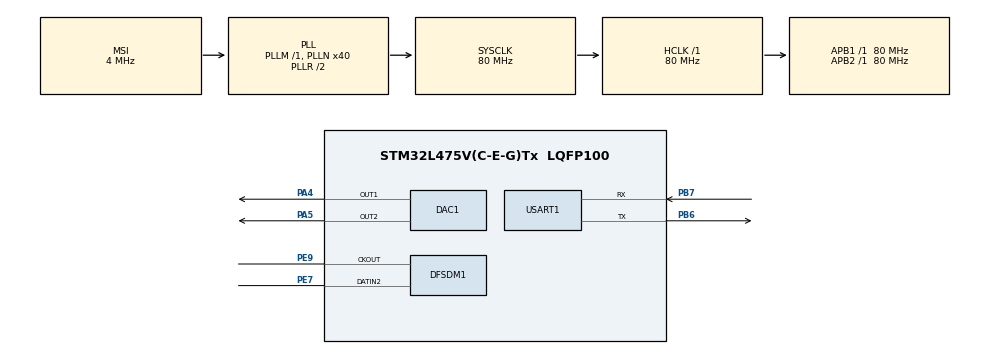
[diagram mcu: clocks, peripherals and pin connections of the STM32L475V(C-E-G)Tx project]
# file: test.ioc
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DAC1.DAC_Channel-DAC_OUT2=DAC_CHANNEL_2
DFSDM1.Divider=32
DFSDM1.FastMode_reg_FIL0=ENABLE
DFSDM1.FastMode_reg_FIL1=ENABLE
DFSDM1.Filter_regChannel_FIL0=DFSDM_CHANNEL_1
DFSDM1.Filter_regChannel_FIL1=DFSDM_CHANNEL_2
DFSDM1.Filter_regContinuousMode_FIL0=DFSDM_CONTINUOUS_CONV_ON
DFSDM1.Filter_regContinuousMode_FIL1=DFSDM_CONTINUOUS_CONV_ON
DFSDM1.Fosr_FIL0=128
DFSDM1.Fosr_FIL1=128
DFSDM1.Iosr_FIL0=1
DFSDM1.Iosr_FIL1=1
DFSDM1.RightBitShift_CH1=0x00
DFSDM1.RightBitShift_CH2=0x00
DFSDM1.Selection=DFSDM_CHANNEL_OUTPUT_CLOCK_AUDIO
DFSDM1.SincOrder_FIL0=DFSDM_FILTER_SINC4_ORDER
DFSDM1.SincOrder_FIL1=DFSDM_FILTER_SINC4_ORDER
DFSDM1.Type_spi_CH1=DFSDM_CHANNEL_SPI_FALLING
Mcu.Family=STM32L4
Mcu.Name=STM32L475V(C-E-G)Tx
Mcu.Package=LQFP100
NVIC.PriorityGroup=NVIC_PRIORITYGROUP_4
PA4.Signal=COMP_DAC11_group
PA5.Signal=COMP_DAC12_group
PB6.Mode=Asynchronous
PB6.Signal=USART1_TX
PB7.Mode=Asynchronous
PB7.Signal=USART1_RX
PE7.Signal=S_DATAIN2DFSDM1
PE9.Signal=S_CKOUTDFSDM1
ProjectManager.HeapSize=0x200
ProjectManager.StackSize=0x400
ProjectManager.TargetToolchain=MDK-ARM V5
RCC.ADCFreq_Value=64000000
RCC.AHBFreq_Value=80000000
RCC.APB1Freq_Value=80000000
RCC.APB1TimFreq_Value=80000000
RCC.APB2Freq_Value=80000000
RCC.APB2TimFreq_Value=80000000
RCC.CortexFreq_Value=80000000
RCC.HCLKFreq_Value=80000000
RCC.HSE_VALUE=8000000
RCC.HSI_VALUE=16000000
RCC.LSE_VALUE=32768
RCC.MSI_VALUE=4000000
RCC.PLLN=40
RCC.PLLSAI1N=32
RCC.SYSCLKFreq_VALUE=80000000
RCC.SYSCLKSource=RCC_SYSCLKSOURCE_PLLCLK
RCC.USBFreq_Value=64000000
RCC.VCOOutputFreq_Value=160000000
SH.COMP_DAC11_group.0=DAC1_OUT1,DAC_OUT1
SH.COMP_DAC12_group.0=DAC1_OUT2,DAC_OUT2
SH.S_CKOUTDFSDM1.0=DFSDM1_CKOUT,PDM_SPI_input_from_ch2_and_internal_clock
SH.S_CKOUTDFSDM1.1=DFSDM1_CKOUT,PDM_SPI_Input_from_ch12_and_Internal_Clock
SH.S_DATAIN2DFSDM1.0=DFSDM1_DATIN2,PDM_SPI_input_from_ch2_and_internal_clock
SH.S_DATAIN2DFSDM1.1=DFSDM1_DATIN2,PDM_SPI_Input_from_ch12_and_Internal_Clock
USART1.VirtualMode-Asynchronous=VM_ASYNC
board=custom

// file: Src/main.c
/**
 ******************************************************************************
 * @file           : main.c
 * @brief          : Main program body
 ******************************************************************************
 ** This notice applies to any and all portions of this file
 * that are not between comment pairs USER CODE BEGIN and
 * USER CODE END. Other portions of this file, whether
 * inserted by the user or by software development tools
 * are owned by their respective copyright owners.
 *
 * COPYRIGHT(c) 2018 STMicroelectronics
 *
 * Redistribution and use in source and binary forms, with or without modification,
 * are permitted provided that the following conditions are met:
 *   1. Redistributions of source code must retain the above copyright notice,
 *      this list of conditions and the following disclaimer.
 *   2. Redistributions in binary form must reproduce the above copyright notice,
 *      this list of conditions and the following disclaimer in the documentation
 *      and/or other materials provided with the distribution.
 *   3. Neither the name of STMicroelectronics nor the names of its contributors
 *      may be used to endorse or promote products derived from this software
 *      without specific prior written permission.
 *
 * THIS SOFTWARE IS PROVIDED BY THE COPYRIGHT HOLDERS AND CONTRIBUTORS "AS IS"
 * AND ANY EXPRESS OR IMPLIED WARRANTIES, INCLUDING, BUT NOT LIMITED TO, THE
 * IMPLIED WARRANTIES OF MERCHANTABILITY AND FITNESS FOR A PARTICULAR PURPOSE ARE
 * DISCLAIMED. IN NO EVENT SHALL THE COPYRIGHT HOLDER OR CONTRIBUTORS BE LIABLE
 * FOR ANY DIRECT, INDIRECT, INCIDENTAL, SPECIAL, EXEMPLARY, OR CONSEQUENTIAL
 * DAMAGES (INCLUDING, BUT NOT LIMITED TO, PROCUREMENT OF SUBSTITUTE GOODS OR
 * SERVICES; LOSS OF USE, DATA, OR PROFITS; OR BUSINESS INTERRUPTION) HOWEVER
 * CAUSED AND ON ANY THEORY OF LIABILITY, WHETHER IN CONTRACT, STRICT LIABILITY,
 * OR TORT (INCLUDING NEGLIGENCE OR OTHERWISE) ARISING IN ANY WAY OUT OF THE USE
 * OF THIS SOFTWARE, EVEN IF ADVISED OF THE POSSIBILITY OF SUCH DAMAGE.
 *
 ******************************************************************************
 */
#include "main.h"
#include "stm32l4xx_hal.h"
#include <math.h>

DAC_HandleTypeDef hdac1;

DFSDM_Filter_HandleTypeDef hdfsdm1_filter0;
DFSDM_Filter_HandleTypeDef hdfsdm1_filter1;
DFSDM_Channel_HandleTypeDef hdfsdm1_channel1;
DFSDM_Channel_HandleTypeDef hdfsdm1_channel2;

UART_HandleTypeDef huart1;

/* USER CODE BEGIN PV */
/* Private variables ---------------------------------------------------------*/

/* USER CODE END PV */

void SystemClock_Config(void);
static void MX_GPIO_Init(void);
static void MX_USART1_UART_Init(void);
static void MX_DFSDM1_Init(void);
static void MX_DAC1_Init(void);

/* USER CODE BEGIN PFP */
/* Private function prototypes -----------------------------------------------*/

/* USER CODE END PFP */

/* USER CODE BEGIN 0 */

int fputc(int ch, FILE *f) {
    while (HAL_OK != HAL_UART_Transmit(&huart1, (uint8_t *) &ch, 1, 30000));
    return ch;
}
int fgetc(FILE *f) {
    uint8_t ch = 0;
    while (HAL_OK != HAL_UART_Receive(&huart1, (uint8_t *)&ch, 1, 30000));
    return ch;
}

/* USER CODE END 0 */

int main(void)
{

    /* MCU Configuration----------------------------------------------------------*/

    /* Reset of all peripherals, Initializes the Flash interface and the Systick. */
    HAL_Init();

    /* Configure the system clock */
    SystemClock_Config();

    /* Initialize all configured peripherals */
    MX_GPIO_Init();
    MX_USART1_UART_Init();
    MX_DFSDM1_Init();
    MX_DAC1_Init();
    /* USER CODE BEGIN 2 */
    HAL_DAC_Start(&hdac1, DAC_CHANNEL_1);
    HAL_DAC_Start(&hdac1, DAC_CHANNEL_2);
    /* USER CODE END 2 */

    /* Infinite loop */
    /* USER CODE BEGIN WHILE */
    HAL_DFSDM_FilterRegularStart(&hdfsdm1_filter0);
    HAL_DFSDM_FilterRegularStart(&hdfsdm1_filter1);

		uint32_t channel0 = 1;
		uint32_t channel1 = 1;
		//int32_t prevflt0Result;
		//int32_t prevflt1Result;
		uint8_t flt0ResultBytes[4];
		uint8_t flt1ResultBytes[4];
		int32_t flt0Result;
		int32_t flt1Result;
		int32_t tempFlt0Result;
		int32_t tempFlt1Result;
		FILE *f;

    while (1)
    {
			//HAL_Delay(50);
			//fputc('c', f);
			//fputc('\n', f);

			//if(flt0Flag ==1){
			//fputc('a', f);
			//fputc('\n', f);

			while (HAL_DFSDM_FilterPollForRegConversion(&hdfsdm1_filter0, 30000) !=  HAL_OK) ;
			flt0Result = HAL_DFSDM_FilterGetRegularValue(&hdfsdm1_filter0, &channel0);
			HAL_DAC_SetValue(&hdac1,DAC_CHANNEL_1,DAC_ALIGN_12B_R,flt0Result);

			/**
			tempFlt0Result = flt0Result & 0xFFF;
			for (int i = 0; i < 4; i++) {
				flt0ResultBytes[3-i] = tempFlt0Result % 10 + '0';
				tempFlt0Result /= 10;
			}
			for (int i = 0; i < 4; i++)
				fputc(flt0ResultBytes[i], f);
			fputc('\n', f);
			*/

			while (HAL_DFSDM_FilterPollForRegConversion(&hdfsdm1_filter1, 30000) !=  HAL_OK) ;
			flt1Result = HAL_DFSDM_FilterGetRegularValue(&hdfsdm1_filter1, &channel1);
			HAL_DAC_SetValue(&hdac1,DAC_CHANNEL_2,DAC_ALIGN_12B_R,flt1Result);

			/**
			if (flt0Result > 200 || flt0Result < 1800) {
				HAL_DAC_SetValue(&hdac1,DAC_CHANNEL_1,DAC_ALIGN_12B_R,flt0Result);
				prevflt0Result = flt0Result;
			}
			else
				HAL_DAC_SetValue(&hdac1,DAC_CHANNEL_1,DAC_ALIGN_12B_R,prevflt0Result);
			**/

			/**
			while (HAL_DFSDM_FilterPollForRegConversion(&hdfsdm1_filter1, 30000) !=  HAL_OK) ;
			flt1Result = HAL_DFSDM_FilterGetRegularValue(&hdfsdm1_filter1, &channel1);
			flt0Result &= 0xFFF;

			if (flt0Result > 200 || flt0Result < 1800) {
				HAL_DAC_SetValue(&hdac1,DAC_CHANNEL_2,DAC_ALIGN_12B_R,flt1Result);
				prevflt1Result = flt1Result;
			}
			else
			HAL_DAC_SetValue(&hdac1,DAC_CHANNEL_2,DAC_ALIGN_12B_R,prevflt1Result);
			*/

			//		fputc(flt0Result, f);
    }
    /* USER CODE END 3 */

}

void SystemClock_Config(void)
{

    RCC_OscInitTypeDef RCC_OscInitStruct;
    RCC_ClkInitTypeDef RCC_ClkInitStruct;
    RCC_PeriphCLKInitTypeDef PeriphClkInit;

    /**Initializes the CPU, AHB and APB busses clocks
    */
    RCC_OscInitStruct.OscillatorType = RCC_OSCILLATORTYPE_MSI;
    RCC_OscInitStruct.MSIState = RCC_MSI_ON;
    RCC_OscInitStruct.MSICalibrationValue = 0;
    RCC_OscInitStruct.MSIClockRange = RCC_MSIRANGE_6;
    RCC_OscInitStruct.PLL.PLLState = RCC_PLL_ON;
    RCC_OscInitStruct.PLL.PLLSource = RCC_PLLSOURCE_MSI;
    RCC_OscInitStruct.PLL.PLLM = 1;
    RCC_OscInitStruct.PLL.PLLN = 40;
    RCC_OscInitStruct.PLL.PLLP = RCC_PLLP_DIV7;
    RCC_OscInitStruct.PLL.PLLQ = RCC_PLLQ_DIV2;
    RCC_OscInitStruct.PLL.PLLR = RCC_PLLR_DIV2;
    if (HAL_RCC_OscConfig(&RCC_OscInitStruct) != HAL_OK)
    {
        _Error_Handler(__FILE__, __LINE__);
    }

    /**Initializes the CPU, AHB and APB busses clocks
    */
    RCC_ClkInitStruct.ClockType = RCC_CLOCKTYPE_HCLK|RCC_CLOCKTYPE_SYSCLK
        |RCC_CLOCKTYPE_PCLK1|RCC_CLOCKTYPE_PCLK2;
    RCC_ClkInitStruct.SYSCLKSource = RCC_SYSCLKSOURCE_PLLCLK;
    RCC_ClkInitStruct.AHBCLKDivider = RCC_SYSCLK_DIV1;
    RCC_ClkInitStruct.APB1CLKDivider = RCC_HCLK_DIV1;
    RCC_ClkInitStruct.APB2CLKDivider = RCC_HCLK_DIV1;

    if (HAL_RCC_ClockConfig(&RCC_ClkInitStruct, FLASH_LATENCY_4) != HAL_OK)
    {
        _Error_Handler(__FILE__, __LINE__);
    }

    PeriphClkInit.PeriphClockSelection = RCC_PERIPHCLK_USART1|RCC_PERIPHCLK_SAI1
        |RCC_PERIPHCLK_DFSDM1;
    PeriphClkInit.Usart1ClockSelection = RCC_USART1CLKSOURCE_PCLK2;
    PeriphClkInit.Sai1ClockSelection = RCC_SAI1CLKSOURCE_PLLSAI1;
    PeriphClkInit.Dfsdm1ClockSelection = RCC_DFSDM1CLKSOURCE_PCLK;
    PeriphClkInit.PLLSAI1.PLLSAI1Source = RCC_PLLSOURCE_MSI;
    PeriphClkInit.PLLSAI1.PLLSAI1M = 1;
    PeriphClkInit.PLLSAI1.PLLSAI1N = 32;
    PeriphClkInit.PLLSAI1.PLLSAI1P = RCC_PLLP_DIV7;
    PeriphClkInit.PLLSAI1.PLLSAI1Q = RCC_PLLQ_DIV2;
    PeriphClkInit.PLLSAI1.PLLSAI1R = RCC_PLLR_DIV2;
    PeriphClkInit.PLLSAI1.PLLSAI1ClockOut = RCC_PLLSAI1_SAI1CLK;
    if (HAL_RCCEx_PeriphCLKConfig(&PeriphClkInit) != HAL_OK)
    {
        _Error_Handler(__FILE__, __LINE__);
    }

    /**Configure the main internal regulator output voltage
    */
    if (HAL_PWREx_ControlVoltageScaling(PWR_REGULATOR_VOLTAGE_SCALE1) != HAL_OK)
    {
        _Error_Handler(__FILE__, __LINE__);
    }

    /**Configure the Systick interrupt time
    */
    HAL_SYSTICK_Config(HAL_RCC_GetHCLKFreq()/1000);

    /**Configure the Systick
    */
    HAL_SYSTICK_CLKSourceConfig(SYSTICK_CLKSOURCE_HCLK);

    /* SysTick_IRQn interrupt configuration */
    HAL_NVIC_SetPriority(SysTick_IRQn, 0, 0);
}

/* DAC1 init function */
static void MX_DAC1_Init(void)
{

    DAC_ChannelConfTypeDef sConfig;

    /**DAC Initialization
    */
    hdac1.Instance = DAC1;
    if (HAL_DAC_Init(&hdac1) != HAL_OK)
    {
        _Error_Handler(__FILE__, __LINE__);
    }

    /**DAC channel OUT1 config
    */
    sConfig.DAC_SampleAndHold = DAC_SAMPLEANDHOLD_DISABLE;
    sConfig.DAC_Trigger = DAC_TRIGGER_NONE;
    sConfig.DAC_OutputBuffer = DAC_OUTPUTBUFFER_ENABLE;
    sConfig.DAC_ConnectOnChipPeripheral = DAC_CHIPCONNECT_DISABLE;
    sConfig.DAC_UserTrimming = DAC_TRIMMING_FACTORY;
    if (HAL_DAC_ConfigChannel(&hdac1, &sConfig, DAC_CHANNEL_1) != HAL_OK)
    {
        _Error_Handler(__FILE__, __LINE__);
    }

    /**DAC channel OUT2 config
    */
    sConfig.DAC_ConnectOnChipPeripheral = DAC_CHIPCONNECT_DISABLE;
    if (HAL_DAC_ConfigChannel(&hdac1, &sConfig, DAC_CHANNEL_2) != HAL_OK)
    {
        _Error_Handler(__FILE__, __LINE__);
    }

}

/* DFSDM1 init function */
static void MX_DFSDM1_Init(void)
{

    hdfsdm1_filter0.Instance = DFSDM1_Filter0;
    hdfsdm1_filter0.Init.RegularParam.Trigger = DFSDM_FILTER_SW_TRIGGER;
    hdfsdm1_filter0.Init.RegularParam.FastMode = ENABLE;
    hdfsdm1_filter0.Init.RegularParam.DmaMode = DISABLE;
    hdfsdm1_filter0.Init.FilterParam.SincOrder = DFSDM_FILTER_SINC4_ORDER;
    hdfsdm1_filter0.Init.FilterParam.Oversampling = 128;
    hdfsdm1_filter0.Init.FilterParam.IntOversampling = 1;
    if (HAL_DFSDM_FilterInit(&hdfsdm1_filter0) != HAL_OK)
    {
        _Error_Handler(__FILE__, __LINE__);
    }

    hdfsdm1_filter1.Instance = DFSDM1_Filter1;
    hdfsdm1_filter1.Init.RegularParam.Trigger = DFSDM_FILTER_SW_TRIGGER;
    hdfsdm1_filter1.Init.RegularParam.FastMode = ENABLE;
    hdfsdm1_filter1.Init.RegularParam.DmaMode = DISABLE;
    hdfsdm1_filter1.Init.FilterParam.SincOrder = DFSDM_FILTER_SINC4_ORDER;
    hdfsdm1_filter1.Init.FilterParam.Oversampling = 128;
    hdfsdm1_filter1.Init.FilterParam.IntOversampling = 1;
    if (HAL_DFSDM_FilterInit(&hdfsdm1_filter1) != HAL_OK)
    {
        _Error_Handler(__FILE__, __LINE__);
    }

    hdfsdm1_channel1.Instance = DFSDM1_Channel1;
    hdfsdm1_channel1.Init.OutputClock.Activation = ENABLE;
    hdfsdm1_channel1.Init.OutputClock.Selection = DFSDM_CHANNEL_OUTPUT_CLOCK_AUDIO;
    hdfsdm1_channel1.Init.OutputClock.Divider = 16;
    hdfsdm1_channel1.Init.Input.Multiplexer = DFSDM_CHANNEL_EXTERNAL_INPUTS;
    hdfsdm1_channel1.Init.Input.DataPacking = DFSDM_CHANNEL_STANDARD_MODE;
    hdfsdm1_channel1.Init.Input.Pins = DFSDM_CHANNEL_FOLLOWING_CHANNEL_PINS;
    hdfsdm1_channel1.Init.SerialInterface.Type = DFSDM_CHANNEL_SPI_FALLING;
    hdfsdm1_channel1.Init.SerialInterface.SpiClock = DFSDM_CHANNEL_SPI_CLOCK_INTERNAL;
    hdfsdm1_channel1.Init.Awd.FilterOrder = DFSDM_CHANNEL_FASTSINC_ORDER;
    hdfsdm1_channel1.Init.Awd.Oversampling = 1;
    hdfsdm1_channel1.Init.Offset = -1024;
    hdfsdm1_channel1.Init.RightBitShift = 0x10;
    if (HAL_DFSDM_ChannelInit(&hdfsdm1_channel1) != HAL_OK)
    {
        _Error_Handler(__FILE__, __LINE__);
    }

    hdfsdm1_channel2.Instance = DFSDM1_Channel2;
    hdfsdm1_channel2.Init.OutputClock.Activation = ENABLE;
    hdfsdm1_channel2.Init.OutputClock.Selection = DFSDM_CHANNEL_OUTPUT_CLOCK_AUDIO;
    hdfsdm1_channel2.Init.OutputClock.Divider = 16;
    hdfsdm1_channel2.Init.Input.Multiplexer = DFSDM_CHANNEL_EXTERNAL_INPUTS;
    hdfsdm1_channel2.Init.Input.DataPacking = DFSDM_CHANNEL_STANDARD_MODE;
    hdfsdm1_channel2.Init.Input.Pins = DFSDM_CHANNEL_SAME_CHANNEL_PINS;
    hdfsdm1_channel2.Init.SerialInterface.Type = DFSDM_CHANNEL_SPI_RISING;
    hdfsdm1_channel2.Init.SerialInterface.SpiClock = DFSDM_CHANNEL_SPI_CLOCK_INTERNAL;
    hdfsdm1_channel2.Init.Awd.FilterOrder = DFSDM_CHANNEL_FASTSINC_ORDER;
    hdfsdm1_channel2.Init.Awd.Oversampling = 1;
    hdfsdm1_channel2.Init.Offset = -1024;
    hdfsdm1_channel2.Init.RightBitShift = 0x10;
    if (HAL_DFSDM_ChannelInit(&hdfsdm1_channel2) != HAL_OK)
    {
        _Error_Handler(__FILE__, __LINE__);
    }

    if (HAL_DFSDM_FilterConfigRegChannel(&hdfsdm1_filter0, DFSDM_CHANNEL_1, DFSDM_CONTINUOUS_CONV_ON) != HAL_OK)
    {
        _Error_Handler(__FILE__, __LINE__);
    }

    if (HAL_DFSDM_FilterConfigRegChannel(&hdfsdm1_filter1, DFSDM_CHANNEL_2, DFSDM_CONTINUOUS_CONV_ON) != HAL_OK)
    {
        _Error_Handler(__FILE__, __LINE__);
    }

}

/* USART1 init function */
static void MX_USART1_UART_Init(void)
{

    huart1.Instance = USART1;
    huart1.Init.BaudRate = 115200;
    huart1.Init.WordLength = UART_WORDLENGTH_8B;
    huart1.Init.StopBits = UART_STOPBITS_1;
    huart1.Init.Parity = UART_PARITY_NONE;
    huart1.Init.Mode = UART_MODE_TX_RX;
    huart1.Init.HwFlowCtl = UART_HWCONTROL_NONE;
    huart1.Init.OverSampling = UART_OVERSAMPLING_16;
    huart1.Init.OneBitSampling = UART_ONE_BIT_SAMPLE_DISABLE;
    huart1.AdvancedInit.AdvFeatureInit = UART_ADVFEATURE_NO_INIT;
    if (HAL_UART_Init(&huart1) != HAL_OK)
    {
        _Error_Handler(__FILE__, __LINE__);
    }

}

/** Pinout Configuration
*/
static void MX_GPIO_Init(void)
{

    /* GPIO Ports Clock Enable */
    __HAL_RCC_GPIOA_CLK_ENABLE();
    __HAL_RCC_GPIOE_CLK_ENABLE();
    __HAL_RCC_GPIOB_CLK_ENABLE();

}

void _Error_Handler(char *file, int line)
{
    while(1)
    {
    }
}

/************************ (C) COPYRIGHT STMicroelectronics *****END OF FILE****/
